# max32572 register map
Vendor: Maxim-Integrated; Series: ARMCM4; File version: 1.0
CPU: CM4 r2p1, little endian, MPU, FPU, 3 interrupt priority bits
Registers are 32-bit, read-write, reset 0x0 unless marked. A register's access mark holds for its fields unless they carry their own. Offsets are from the block's base; [hi:lo] are bit positions; {n}, {i} and the like mark numbered series; 'fields as' and 'values as' point back to an identical list.

## SMON — The Security Monitor block used to monitor system threat conditions.
Base 0x40004000
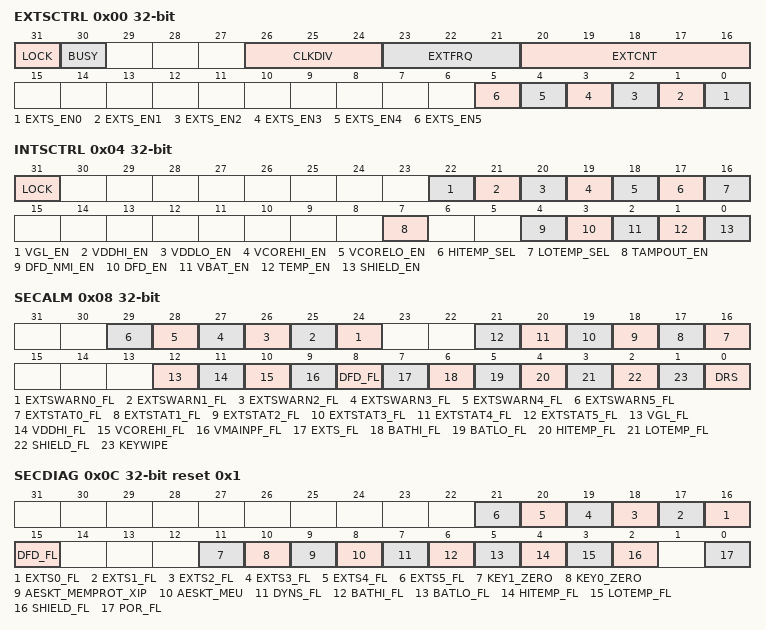
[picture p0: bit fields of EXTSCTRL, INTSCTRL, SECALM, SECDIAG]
0x00 EXTSCTRL (reset mask 0x3800FFC0) — External Sensor Control Register.
  [31] LOCK — Lock Register. Once locked, the EXTSCN register can no longer be modified. Only a battery disconnect will clear this bit. VBAT powers this register.
    0=unlocked; 1=locked
  [30] BUSY ro — Busy. This bit is set to 1 by hardware after EXTSCN register is written to. This bit is automatically cleared to 0 after this register information has been transferred to the security monitor domain.
    0=idle; 1=busy (Update in Progress.)
  [26:24] CLKDIV — Clock Divide. These bits are used to divide the 8KHz input clock. The resulting divided clock is used for all logic within the Security Monitor Block. Note: If the input clock is divided with these bits, the error count threshold table and output frequency will be affected accordingly with the same divide factor.
    0=div1 (Divide by 1 (8000 Hz).); 1=div2 (Divide by 2 (4000 Hz).); 2=div4 (Divide by 4 (2000 Hz).); 3=div8 (Divide by 8 (1000 Hz).); 4=div16 (Divide by 16 (500 Hz).); 5=div32 (Divide by 32 (250 Hz).); 6=div64 (Divide by 64 (125 Hz).)
  [23:21] EXTFRQ — External Sensor Frequency. These bits define the frequency at which the external sensors are clocked to/from the EXTS_IN and EXTS_OUT pair.
    0=freq2000Hz (Div 4 (2000Hz).); 1=freq1000Hz (Div 8 (1000Hz).); 2=freq500Hz (Div 16 (500Hz).); 3=freq250Hz (Div 32 (250Hz).); 4=freq125Hz (Div 64 (125Hz).); 5=freq63Hz (Div 128 (63Hz).); 6=freq31Hz (Div 256 (31Hz).)
  [20:16] EXTCNT — External Sensor Error Counter. These bits set the number of external sensor accepted mismatches that have to occur within a single bit period before an external sensor alarm is triggered.
  [n] EXTS_EN{n} (n=0..5) — External Sensor Enable for input/output pair {n}.
    0=dis (Disable.); 1=en (Enable.)
0x04 INTSCTRL (reset mask 0x7F00FFF7) — Internal Sensor Control Register.
  [31] LOCK — Lock Register. Once locked, the INTSCN register can no longer be modified. Only a battery disconnect will clear this bit. VBAT powers this register.
    0=unlocked; 1=locked
  [22] VGL_EN — Voltage Glitch Detection Enable.
    0=dis (Disable.); 1=en (Enable.)
  [21] VDDHI_EN — VDD Overvoltage Detect Enable.
    0=dis (Disable.); 1=en (Enable.)
  [20] VDDLO_EN — VDD Undervoltage Detect Enable.
    0=dis (Disable.); 1=en (Enable.)
  [19] VCOREHI_EN — VCORE Overvoltage Detect Enable.
    0=dis (Disable.); 1=en (Enable.)
  [18] VCORELO_EN — VCORE Undervoltage Detect Enable.
    0=dis (Disable.); 1=en (Enable.)
  [17] HITEMP_SEL — High Temperature Detection Select.
  [16] LOTEMP_SEL — Low Temperature Detection Select.
    0=neg50C (-50 degrees C.); 1=neg30C (-30 degrees C.)
  [7] TAMPOUT_EN — Tamper Output Enable.
  [4] DFD_NMI_EN — Digital Fault NMI Enable
  [3] DFD_EN — Digital Fault Dector Enable
  [2] VBAT_EN — Battery Monitor Enable.
    0=dis (Disable.); 1=en (Enable.)
  [1] TEMP_EN — Temperature Sensor Enable.
    0=dis (Disable.); 1=en (Enable.)
  [0] SHIELD_EN — Die Shield Enable.
    0=dis (Disable.); 1=en (Enable.)
0x08 SECALM reset not defined — Security Alarm Register.
  [n+24] EXTSWARN{n}_FL (n=0..5) — External Sensor {n} Warning Ready flag. The tamper detect warning flags are set, regardless of whether the external sensors are enabled.
    0=noEvent (The event has not occurred.); 1=occurred (The event has occurred.)
  [n+16] EXTSTAT{n}_FL (n=0..5) — External Sensor {n} Detect. The tamper detect is only active when it is enabled. This bits needs to be cleared in software after a tamper event to re-arm the sensor.
    values as EXTSWARN0_FL
  [12] VGL_FL — Voltage Glitch Detection Flag.
    values as EXTSWARN0_FL
  [11] VDDHI_FL — VDD Overvoltage Flag.
    values as EXTSWARN0_FL
  [10] VCOREHI_FL — VCORE Overvoltage Detect Flag.
    values as EXTSWARN0_FL
  [9] VMAINPF_FL — VMAIN Power Fail Flag.
    values as EXTSWARN0_FL
  [8] DFD_FL — Digital Fault Detector.
    values as EXTSWARN0_FL
  [7] EXTS_FL — External Sensor Flag. This bit is set to 1 when any of the EXTSTAT bits are set.
    values as EXTSWARN0_FL
  [6] BATHI_FL — Battery Overvoltage Detect.
    values as EXTSWARN0_FL
  [5] BATLO_FL — Battery Undervoltage Detect.
    values as EXTSWARN0_FL
  [4] HITEMP_FL — High Temperature Detect.
    values as EXTSWARN0_FL
  [3] LOTEMP_FL — Low Temperature Detect.
    values as EXTSWARN0_FL
  [2] SHIELD_FL — Die Shield Flag.
    values as EXTSWARN0_FL
  [1] KEYWIPE — Key Wipe Trigger. Set to 1 to initiate a wipe of the AES key register. It does not reset the part, or log a timestamp. AES and DES registers are not affected by this bit. This bit is automatically cleared to 0 after the keys have been wiped.
    0=complete (No operation/complete.); 1=Start operation
  [0] DRS — Destructive Reset Trigger. Setting this bit will generate a DRS. This bit is self-cleared by hardware.
    0=complete (No operation/complete.); 1=Start operation
0x0C SECDIAG reset 0x1 (reset mask 0xFFC0FE02) — Security Diagnostic Register.
  [n+16] EXTS{n}_FL (n=0..5) — External Sensor {n} Detect.
    values as SECALM.EXTSWARN0_FL
  [15] DFD_FL — Digital Fault Detector Flag.
    values as SECALM.EXTSWARN0_FL
  [11] KEY1_ZERO — Key1 Cleared.
    0=incomplete (Key has not been transferred.); 1=complete (Key has been transferred.)
  [10] KEY0_ZERO — Key0 Cleared.
    values as KEY1_ZERO
  [9] AESKT_MEMPROT_XIP — AES Key Transfer. This bit is set to 1 when AES MDU Key has been transferred from the TRNG to the battery backed AES key register. This bit can only be reset by a BOR.
    values as KEY1_ZERO
  [8] AESKT_MEU — AES Key Transfer. This bit is set to 1 when the NVSRAM 256 bit AES key is generated by the TRNG and loaded to the AES KEY NVSRAM Encryption registers. This bit is reset by a POR or DRS.
    values as KEY1_ZERO
  [7] DYNS_FL — Dynamic Sensor Flag. This bit is set to 1 when any of the EXTSTAT bits are set.
    values as SECALM.EXTSWARN0_FL
  [6] BATHI_FL — Battery Overvoltage Detect.
    values as SECALM.EXTSWARN0_FL
  [5] BATLO_FL — Battery Undervoltage Detect.
    values as SECALM.EXTSWARN0_FL
  [4] HITEMP_FL — High Temperature Detect.
    values as SECALM.EXTSWARN0_FL
  [3] LOTEMP_FL — Low Temperature Detect.
    values as SECALM.EXTSWARN0_FL
  [2] SHIELD_FL — Die Shield Flag.
    values as SECALM.EXTSWARN0_FL
  [0] POR_FL — Power-On-Reset Flag. This bit is set once the power supply is conneted.
    values as SECALM.EXTSWARN0_FL
0x10 DLRTC ro reset not defined — DRS Log RTC Value. This register contains the 32 bit value in the RTC second register when the last DRS event occurred.
  [31:0] DLRTC — DRS Log RTC Value. This register contains the 32 bit value in the RTC second register when the last DRS event occured.
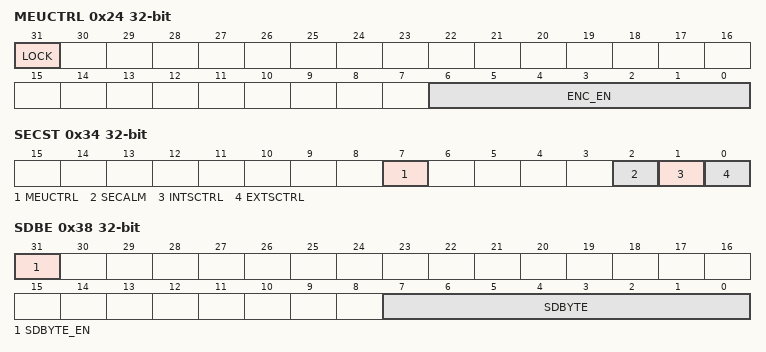
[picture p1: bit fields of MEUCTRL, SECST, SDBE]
0x24 MEUCTRL reset not defined — MEU Configuration
  [31] LOCK
  [6:0] ENC_EN — Configuration plain/encrypted area of the backed NVSRAM.
0x34 SECST ro — Security Monitor Status Register.
  [all] fields
    0=allowed (Access authorized.); 1=notAllowed (Access not authorized.)
  [7] MEUCTRL — Security Alarm Register Status.
  [2] SECALM — Security Alarm Register Status.
  [1] INTSCTRL — Internal Sensor Control Register Status.
  [0] EXTSCTRL — External Sensor Control Register Status.
0x38 SDBE — Security Monitor Self Destruct Byte.
  [31] SDBYTE_EN — Self-Destruct Byte Enable.
  [7:0] SDBYTE — Self Destruct Byte
